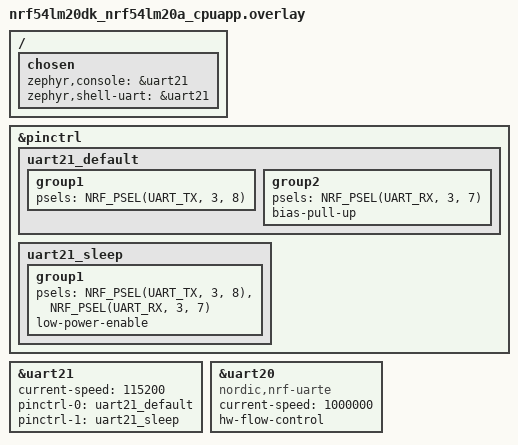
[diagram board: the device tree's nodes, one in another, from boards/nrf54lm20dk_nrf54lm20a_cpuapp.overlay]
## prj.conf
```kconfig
# CONFIG_CONSOLE=n
CONFIG_STDOUT_CONSOLE=n
# CONFIG_UART_CONSOLE=n
CONFIG_GPIO=y
CONFIG_SERIAL=y
CONFIG_UART_INTERRUPT_DRIVEN=y

CONFIG_SYSTEM_WORKQUEUE_STACK_SIZE=512

CONFIG_BT=y
CONFIG_BT_HCI_RAW=y
CONFIG_BT_HCI_RAW_H4=y
CONFIG_BT_HCI_RAW_H4_ENABLE=y
CONFIG_BT_MAX_CONN=16

# Enable and adjust the below value as necessary to match Controller values
# CONFIG_BT_BUF_EVT_RX_COUNT=16
# CONFIG_BT_BUF_EVT_RX_SIZE=255
# CONFIG_BT_BUF_ACL_RX_SIZE=255
# CONFIG_BT_BUF_ACL_TX_SIZE=251
# CONFIG_BT_BUF_CMD_TX_SIZE=255

CONFIG_BT_MAX_CONN=20
CONFIG_BT_CTLR_SDC_PERIPHERAL_COUNT=0
CONFIG_BT_PERIPHERAL=n
CONFIG_BT_BROADCASTER=y
CONFIG_BT_OBSERVER=y

# CONFIG_LOG=y
# CONFIG_RTT_CONSOLE=y


CONFIG_CONSOLE=y
CONFIG_LOG=y
CONFIG_LOG_BUFFER_SIZE=4096
CONFIG_UART_CONSOLE=y
CONFIG_LOG_BACKEND_UART=y
# CONFIG_LOG_DEFAULT_LEVEL=4

CONFIG_LOG_BACKEND_SHOW_COLOR=n
CONFIG_LOG_PROCESS_THREAD_STACK_SIZE=1024

CONFIG_BT_CTLR_ADV_EXT=y
CONFIG_BT_EXT_ADV=y

# CONFIG_LOG_RUNTIME_FILTERING=y
CONFIG_LOG_MAX_LEVEL=4
CONFIG_LOG_DEFAULT_LEVEL=3
CONFIG_BT_HCI_CORE_LOG_LEVEL_DBG=y
CONFIG_BT_L2CAP_LOG_LEVEL_DBG=y
CONFIG_BT_ATT_LOG_LEVEL_DBG=y
CONFIG_BT_GATT_LOG_LEVEL_DBG=y
```

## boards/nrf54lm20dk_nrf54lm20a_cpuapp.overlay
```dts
/*
 * Copyright (c) 2024 Nordic Semiconductor ASA
 *
 * SPDX-License-Identifier: Apache-2.0
 */

#include <zephyr/dt-bindings/pinctrl/nrf-pinctrl.h>

/ {
	chosen {
        zephyr,console = &uart21;
        zephyr,shell-uart = &uart21;
	};
};

&pinctrl {
    uart21_default: uart21_default {
        group1 {
            psels = <NRF_PSEL(UART_TX, 3, 8)>;
        };
        group2 {
            psels = <NRF_PSEL(UART_RX, 3, 7)>;
            bias-pull-up;
        };
    };
    uart21_sleep: uart21_sleep {
        group1 {
            psels = <NRF_PSEL(UART_TX, 3, 8)>, <NRF_PSEL(UART_RX, 3, 7)>;
            low-power-enable;
        };
    };
};

&uart21 {
    status = "okay";
    current-speed = <115200>;
    pinctrl-0 = <&uart21_default>;
    pinctrl-1 = <&uart21_sleep>;
    pinctrl-names = "default", "sleep";
};


&uart20 {
	compatible = "nordic,nrf-uarte";
	current-speed = <1000000>;
	status = "okay";
	hw-flow-control;
};
```

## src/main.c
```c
/*
 * Copyright (c) 2016 Nordic Semiconductor ASA
 * Copyright (c) 2015-2016 Intel Corporation
 *
 * SPDX-License-Identifier: Apache-2.0
 */

#include <errno.h>
#include <stddef.h>
#include <stdio.h>
#include <string.h>

#include <zephyr/kernel.h>
#include <zephyr/arch/cpu.h>
#include <zephyr/sys/byteorder.h>
#include <zephyr/logging/log_ctrl.h>
#include <zephyr/logging/log.h>
#include <zephyr/sys/util.h>

#include <zephyr/device.h>
#include <zephyr/init.h>
#include <zephyr/drivers/uart.h>

#include <zephyr/sys/atomic.h>
#include <zephyr/net_buf.h>
#include <zephyr/bluetooth/bluetooth.h>
#include <zephyr/bluetooth/l2cap.h>
#include <zephyr/bluetooth/hci.h>
#include <zephyr/bluetooth/buf.h>
#include <zephyr/bluetooth/hci_raw.h>
#include <zephyr/bluetooth/hci_vs.h>

#define LOG_MODULE_NAME hci_uart
LOG_MODULE_REGISTER(LOG_MODULE_NAME,LOG_LEVEL_DBG);

static const struct device *const hci_uart_dev =
	DEVICE_DT_GET(DT_CHOSEN(zephyr_bt_c2h_uart));
static K_THREAD_STACK_DEFINE(tx_thread_stack, CONFIG_BT_HCI_TX_STACK_SIZE);
static struct k_thread tx_thread_data;
static K_FIFO_DEFINE(tx_queue);

/* RX in terms of bluetooth communication */
static K_FIFO_DEFINE(uart_tx_queue);

#define H4_CMD 0x01
#define H4_ACL 0x02
#define H4_SCO 0x03
#define H4_EVT 0x04
#define H4_ISO 0x05

/* Receiver states. */
#define ST_IDLE 0	/* Waiting for packet type. */
#define ST_HDR 1	/* Receiving packet header. */
#define ST_PAYLOAD 2	/* Receiving packet payload. */
#define ST_DISCARD 3	/* Dropping packet. */

/* Length of a discard/flush buffer.
 * This is sized to align with a Bluetooth HCI packet:
 * 1 byte H:4 header + 32 bytes ACL/event data
 * Bigger values might overflow the stack since this is declared as a local
 * variable, smaller ones will force the caller to call into discard more
 * often.
 */
#define H4_DISCARD_LEN 33

static int h4_read(const struct device *uart, uint8_t *buf, size_t len)
{
	int rx = uart_fifo_read(uart, buf, len);

	LOG_DBG("read %d req %d", rx, len);

	return rx;
}

static bool valid_type(uint8_t type)
{
	return (type == H4_CMD) | (type == H4_ACL) | (type == H4_ISO);
}

/* Function expects that type is validated and only CMD, ISO or ACL will be used. */
static uint32_t get_len(const uint8_t *hdr_buf, uint8_t type)
{
	switch (type) {
	case H4_CMD:
		return ((const struct bt_hci_cmd_hdr *)hdr_buf)->param_len;
	case H4_ISO:
		return bt_iso_hdr_len(
			sys_le16_to_cpu(((const struct bt_hci_iso_hdr *)hdr_buf)->len));
	case H4_ACL:
		return sys_le16_to_cpu(((const struct bt_hci_acl_hdr *)hdr_buf)->len);
	default:
		LOG_ERR("Invalid type: %u", type);
		return 0;
	}
}

/* Function expects that type is validated and only CMD, ISO or ACL will be used. */
static int hdr_len(uint8_t type)
{
	switch (type) {
	case H4_CMD:
		return sizeof(struct bt_hci_cmd_hdr);
	case H4_ISO:
		return sizeof(struct bt_hci_iso_hdr);
	case H4_ACL:
		return sizeof(struct bt_hci_acl_hdr);
	default:
		LOG_ERR("Invalid type: %u", type);
		return 0;
	}
}

static void rx_isr(void)
{
	static struct net_buf *buf;
	static int remaining;
	static uint8_t state;
	static uint8_t type;
	static uint8_t hdr_buf[MAX(sizeof(struct bt_hci_cmd_hdr),
			sizeof(struct bt_hci_acl_hdr))];
	int read;

	do {
		switch (state) {
		case ST_IDLE:
			/* Get packet type */
			read = h4_read(hci_uart_dev, &type, sizeof(type));
			/* since we read in loop until no data is in the fifo,
			 * it is possible that read = 0.
			 */
			if (read) {
				if (valid_type(type)) {
					/* Get expected header size and switch
					 * to receiving header.
					 */
					remaining = hdr_len(type);
					state = ST_HDR;
				} else {
					LOG_WRN("Unknown header %d", type);
				}
			}
			break;
		case ST_HDR:
			read = h4_read(hci_uart_dev,
				       &hdr_buf[hdr_len(type) - remaining],
				       remaining);
			remaining -= read;
			if (remaining == 0) {
				/* Header received. Allocate buffer and get
				 * payload length. If allocation fails leave
				 * interrupt. On failed allocation state machine
				 * is reset.
				 */
				buf = bt_buf_get_tx(bt_buf_type_from_h4(type, BT_BUF_OUT),
						    K_NO_WAIT, NULL, 0);
				if (!buf) {
					LOG_ERR("No available command buffers!");
					state = ST_IDLE;
					return;
				}

				remaining = get_len(hdr_buf, type);

				net_buf_add_mem(buf, hdr_buf, hdr_len(type));
				if (remaining > net_buf_tailroom(buf)) {
					LOG_ERR("Not enough space in buffer");
					net_buf_unref(buf);
					state = ST_DISCARD;
				} else {
					state = ST_PAYLOAD;
				}

			}
			break;
		case ST_PAYLOAD:
			read = h4_read(hci_uart_dev, net_buf_tail(buf),
				       remaining);
			buf->len += read;
			remaining -= read;
			if (remaining == 0) {
				/* Packet received */
				LOG_DBG("putting RX packet in queue.");
				k_fifo_put(&tx_queue, buf);
				state = ST_IDLE;
			}
			break;
		case ST_DISCARD:
		{
			uint8_t discard[H4_DISCARD_LEN];
			size_t to_read = MIN(remaining, sizeof(discard));

			read = h4_read(hci_uart_dev, discard, to_read);
			remaining -= read;
			if (remaining == 0) {
				state = ST_IDLE;
			}

			break;

		}
		default:
			read = 0;
			__ASSERT_NO_MSG(0);
			break;

		}
	} while (read);
}

static void tx_isr(void)
{
	static struct net_buf *buf;
	int len;

	if (!buf) {
		buf = k_fifo_get(&uart_tx_queue, K_NO_WAIT);
		if (!buf) {
			uart_irq_tx_disable(hci_uart_dev);
			return;
		}
	}

	len = uart_fifo_fill(hci_uart_dev, buf->data, buf->len);
	net_buf_pull(buf, len);
	if (!buf->len) {
		net_buf_unref(buf);
		buf = NULL;
	}
}

static void bt_uart_isr(const struct device *unused, void *user_data)
{
	ARG_UNUSED(unused);
	ARG_UNUSED(user_data);

	while (uart_irq_update(hci_uart_dev) && uart_irq_is_pending(hci_uart_dev)) {
		if (!(uart_irq_rx_ready(hci_uart_dev) ||
		      uart_irq_tx_ready(hci_uart_dev))) {
			LOG_DBG("spurious interrupt");
		}

		if (uart_irq_tx_ready(hci_uart_dev)) {
			tx_isr();
		}

		if (uart_irq_rx_ready(hci_uart_dev)) {
			rx_isr();
		}
	}
}

/* ----------------------------------------------------------------------------
 * HCI_Reset Set_Event_Mask workaround
 *
 * Some HCI hosts (notably Android) reset the controller but never send
 * HCI_Set_Event_Mask afterwards. Per Core 6.3 Vol 4 Part E 7.3.1, the spec
 * default of the classic Event Mask is 0x00001FFFFFFFFFFF, which leaves bit
 * 61 (LE Meta event) CLEARED. The SoftDevice Controller follows the spec
 * strictly: while bit 61 is clear it filters out every LE event before any
 * LE Event Mask is consulted, so scanning succeeds at the link layer but the
 * host never sees a single report.
 *
 * Workaround: after every successful HCI_Reset, inject HCI_Set_Event_Mask
 * (FF*8) and swallow the matching Command_Complete so the host's command-
 * pipeline accounting stays consistent. If the host sends its own
 * HCI_Set_Event_Mask later, that value replaces ours (the SDC just memcpy's
 * it), so this only restores a sane default and does not override host
 * policy.
  * --------------------------------------------------------------------------*/
static atomic_t cmd_completes_to_swallow;

static bool buf_is_cmd_complete_for_opcode(const struct net_buf *buf,
					   uint16_t opcode)
{
	/* CONFIG_BT_HCI_RAW_H4=y => event buffers carry the H:4 type byte.
	 * Layout for Command Complete:
	 *   [0]=H4_EVT, [1]=evt_code, [2]=param_len, [3]=ncmd,
	 *   [4..5]=opcode, [6]=status
	 */
	if (buf->len < 6 || buf->data[0] != H4_EVT ||
	    buf->data[1] != BT_HCI_EVT_CMD_COMPLETE) {
		return false;
	}
	return sys_get_le16(&buf->data[4]) == opcode;
}

static void inject_enable_all_events(void)
{
	struct net_buf *cmd;
	struct bt_hci_cmd_hdr hdr;
	uint8_t mask[8];

	cmd = bt_buf_get_tx(BT_BUF_CMD, K_NO_WAIT, NULL, 0);
	if (!cmd) {
		LOG_WRN("HCI_Reset workaround: out of TX bufs, skipping inject");
		return;
	}

	hdr.opcode = sys_cpu_to_le16(BT_HCI_OP_SET_EVENT_MASK);
	hdr.param_len = sizeof(mask);
	net_buf_add_mem(cmd, &hdr, sizeof(hdr));
	memset(mask, 0xFF, sizeof(mask));
	net_buf_add_mem(cmd, mask, sizeof(mask));

	/* Increment BEFORE bt_send so the RX loop cannot race us and forward
	 * the CC to the host.
	 */
	atomic_inc(&cmd_completes_to_swallow);

	if (bt_send(cmd) != 0) {
		atomic_dec(&cmd_completes_to_swallow);
		net_buf_unref(cmd);
		LOG_WRN("HCI_Reset workaround: bt_send failed");
	}
}

static void tx_thread(void *p1, void *p2, void *p3)
{
	while (1) {
		struct net_buf *buf;
		int err;

		/* Wait until a buffer is available */
		buf = k_fifo_get(&tx_queue, K_FOREVER);

		/* Pass buffer to the stack */
		err = bt_send(buf);
		if (err) {
			LOG_ERR("Unable to send (err %d)", err);
			net_buf_unref(buf);
		}

		/* Give other threads a chance to run if tx_queue keeps getting
		 * new data all the time.
		 */
		k_yield();
	}
}

static int h4_send(struct net_buf *buf)
{
	LOG_DBG("buf %p type %u len %u", buf, buf->data[0], buf->len);

	k_fifo_put(&uart_tx_queue, buf);
	uart_irq_tx_enable(hci_uart_dev);

	return 0;
}

#if defined(CONFIG_BT_CTLR_ASSERT_HANDLER)
void bt_ctlr_assert_handle(char *file, uint32_t line)
{
	/* Disable interrupts, this is unrecoverable */
	(void)irq_lock();

	if (IS_ENABLED(CONFIG_BT_HCI_VS_FATAL_ERROR)) {
		struct net_buf *buf;

		/* Prepare vendor specific HCI error event */
		buf = hci_vs_err_assert(file, line);
		if (buf != NULL) {
			uint32_t len;
			uint8_t *data;

			/* Disable interrupt driven, and use polling to be able to transmit while
			 * being in highest priority ISR.
			 */
			uart_irq_rx_disable(hci_uart_dev);
			uart_irq_tx_disable(hci_uart_dev);

			/* Send the event over UART */
			data = &buf->data[0];
			len = buf->len;
			while (len) {
				uart_poll_out(hci_uart_dev, *data);
				data++;
				len--;
			}
		} else {
			LOG_ERR("Can't create Fatal Error HCI event: %s at %d", __FILE__, __LINE__);
		}

		LOG_ERR("Halting system");
	} else {
		LOG_ERR("Controller assert in: %s at %d", file, line);
	}

	/* Flush the logs before locking the CPU */
	LOG_PANIC();

	while (true) {
		k_cpu_idle();
	};

	CODE_UNREACHABLE;
}
#endif /* CONFIG_BT_CTLR_ASSERT_HANDLER */

#if defined(CONFIG_BT_HCI_VS_FATAL_ERROR)
void k_sys_fatal_error_handler(unsigned int reason, const struct arch_esf *esf)
{
	/* Disable interrupts, this is unrecoverable */
	(void)irq_lock();

	/* Generate an error event only when there is a stack frame */
	if (esf != NULL) {
		struct net_buf *buf;

		/* Prepare vendor specific HCI error event */
		buf = hci_vs_err_stack_frame(reason, esf);
		if (buf != NULL) {
			uint32_t len;
			uint8_t *data;

			/* Disable interrupt driven, and use polling to be able to transmit while
			 * being in highest priority ISR.
			 */
			uart_irq_rx_disable(hci_uart_dev);
			uart_irq_tx_disable(hci_uart_dev);

			/* Send the event over UART */
			data = &buf->data[0];
			len = buf->len;
			while (len) {
				uart_poll_out(hci_uart_dev, *data);
				data++;
				len--;
			}
		} else {
			LOG_ERR("Can't create Fatal Error HCI event.\n");
		}
	}

	LOG_ERR("Halting system");

	/* Flush the logs before locking the CPU */
	LOG_PANIC();

	while (true) {
		k_cpu_idle();
	};

	CODE_UNREACHABLE;
}
#endif /* CONFIG_BT_HCI_VS_FATAL_ERROR */

static int hci_uart_init(void)
{
	LOG_DBG("");

	if (!device_is_ready(hci_uart_dev)) {
		LOG_ERR("HCI UART %s is not ready", hci_uart_dev->name);
		return -EINVAL;
	}

	uart_irq_rx_disable(hci_uart_dev);
	uart_irq_tx_disable(hci_uart_dev);

	uart_irq_callback_set(hci_uart_dev, bt_uart_isr);

	uart_irq_rx_enable(hci_uart_dev);

	return 0;
}

SYS_INIT(hci_uart_init, APPLICATION, CONFIG_KERNEL_INIT_PRIORITY_DEVICE);

#if defined(CONFIG_BT_LL_SOFTDEVICE)
void bt_ctlr_set_public_addr(const uint8_t *addr);

static void set_fixed_public_addr(void)
{
	/*
	 * SDC VS Write BD_ADDR expects the six address bytes as they are sent over HCI,
	 * i.e. least significant byte first.
	 */
	static const uint8_t public_addr[6] = {
		0x1e, 0x90, 0xf2, 0x27, 0x87, 0x04 /* 04:87:27:f2:90:1e */
	};

	bt_ctlr_set_public_addr(public_addr);
	LOG_WRN("Controller BD_ADDR forced to 04:87:27:f2:90:1e");
}
#else
static void set_fixed_public_addr(void)
{
}
#endif

int main(void)
{
	/* incoming events and data from the controller */
	static K_FIFO_DEFINE(rx_queue);
	int err;

	LOG_DBG("Start");
	__ASSERT(hci_uart_dev, "UART device is NULL");
	LOG_INF("App started");
    LOG_DBG("App debug message");

	/* Enable the raw interface, this will in turn open the HCI driver */
	bt_enable_raw(&rx_queue);
	set_fixed_public_addr();

	if (IS_ENABLED(CONFIG_BT_WAIT_NOP)) {
		/* Issue a Command Complete with NOP */
		int i;

		const struct {
			const uint8_t h4;
			const struct bt_hci_evt_hdr hdr;
			const struct bt_hci_evt_cmd_complete cc;
		} __packed cc_evt = {
			.h4 = H4_EVT,
			.hdr = {
				.evt = BT_HCI_EVT_CMD_COMPLETE,
				.len = sizeof(struct bt_hci_evt_cmd_complete),
			},
			.cc = {
				.ncmd = 1,
				.opcode = sys_cpu_to_le16(BT_OP_NOP),
			},
		};

		for (i = 0; i < sizeof(cc_evt); i++) {
			uart_poll_out(hci_uart_dev,
				      *(((const uint8_t *)&cc_evt)+i));
		}
	}

	/* Spawn the TX thread and start feeding commands and data to the
	 * controller
	 */
	k_thread_create(&tx_thread_data, tx_thread_stack,
			K_THREAD_STACK_SIZEOF(tx_thread_stack), tx_thread,
			NULL, NULL, NULL, K_PRIO_COOP(7), 0, K_NO_WAIT);
	k_thread_name_set(&tx_thread_data, "HCI uart TX");

	while (1) {
		struct net_buf *buf;

		buf = k_fifo_get(&rx_queue, K_FOREVER);

		/* HCI_Reset workaround: hide the Command Complete for our injected
		 * HCI_Set_Event_Mask so the host never sees a Command Complete for a
		 * command it did not send.
		 */
		if (atomic_get(&cmd_completes_to_swallow) > 0 &&
		    buf_is_cmd_complete_for_opcode(buf,
						   BT_HCI_OP_SET_EVENT_MASK)) {
			atomic_dec(&cmd_completes_to_swallow);
			net_buf_unref(buf);
			continue;
		}

		/* HCI_Reset workaround: after every successful Command Complete for Reset,
		 * inject HCI_Set_Event_Mask(FF*8) BEFORE forwarding the Command Complete
		 * to the host.
		 */
		if (buf_is_cmd_complete_for_opcode(buf, BT_HCI_OP_RESET) &&
		    buf->len >= 7 && buf->data[6] == 0x00) {
			inject_enable_all_events();
		}

		err = h4_send(buf);
		if (err) {
			LOG_ERR("Failed to send");
		}
	}
	return 0;
}
```
